# GPIO7 register map
Vendor: Texas Instruments
Peripheral module from a debugger description file (folder am574x).
Registers are 32-bit, read-write, reset 0x0 unless marked. A register's access mark holds for its fields unless they carry their own. Offsets are as the file gives them; lines under a group give offsets from that group; [hi:lo] are bit positions; {n}, {i} and the like mark numbered series; 'fields as' and 'values as' point back to an identical list; <NAME> marks a mode.

## GPIO7
0x00 GPIO_REVISION ro reset not defined — IP revision identifier (X.Y.R)
  [31:0] REVISION — IP revision
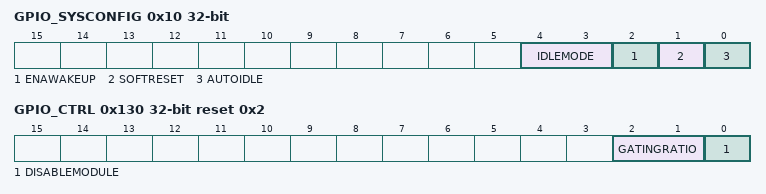
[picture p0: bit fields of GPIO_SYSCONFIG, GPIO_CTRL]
0x10 GPIO_SYSCONFIG access per field — System configuration register
  [4:3] IDLEMODE rw — 0x0: Force-idle: An IDLE request is acknowledged unconditionally.
    1=No-idle: An IDLE request is never acknowledged; 2=Smart-idle: The acknowledgment to an IDLE request is given based on the internal activity (see, System Power Management and Wakeup); 3=SmartIdleWakeup
  [2] ENAWAKEUP rw — Wake-up control.
    0=Disable (Wake-up generation is disabled.); 1=Enable (Wake-up capability is enabled upon expected transition on input GPIO pin)
  [1] SOFTRESET rw — Software reset. Set this bit to 1 to trigger a module reset. The bit is automatically reset by the hardware. During reads, it always returns 0.
    0=Normal mode; 1=Reset (The module is reset.)
  [0] AUTOIDLE rw — OCP clock gating control.
    0=FreeRun (Internal interface OCP clock is free-running.); 1=Automatic internal OCP clock gating, based on the OCP interface activity
0x20 GPIO_EOI access per field — Software end of interrupt.
  [0] LINE_NUMBER wo — Software End Of Interrupt (EOI) control.
    0=EOI_0 (EOI for interrupt line number 0. Read returns 0.); 1=EOI_1 (EOI for interrupt line number 1. Read returns 0.)
0x24 GPIO_IRQSTATUS_RAW_0 — Per-event raw interrupt status vector, showing all active events (enabled and not enabled), (corresponding to first line of interrupt)
  [31:0] INTLINE — Status raw for interrupt line. Writing '1' to a bit will set it to '1.' Writing '0' has no effect
0x28 GPIO_IRQSTATUS_RAW_1 — Per-event raw interrupt status vector, showing all active events (enabled and not enabled), (corresponding to second line of interrupt)
  [31:0] INTLINE — Status raw for interrupt line Writing '1' to a bit will set it to '1.' Writing '0' has no effect
0x2C GPIO_IRQSTATUS_0 — Per-event interrupt status vector, showing all active and enabled events (corresponding to first line of interrupt)
  [31:0] INTLINE — Status for interrupt line Writing 1 to a bit will clear it to 0. Writing 0 has no effect.
0x30 GPIO_IRQSTATUS_1 — Per-event enabled interrupt status vector, showing all active and enabled events (corresponding to second line of interrupt)
  fields as GPIO_IRQSTATUS_0
0x34 GPIO_IRQSTATUS_SET_0 — Per-event interrupt-enable set vector (corresponding to first line of interrupt)
  [31:0] INTLINE — Status set for interrupt line Writing 1 to a bit enables the corresponding interrupt event. Writing 0 has no effect.
0x38 GPIO_IRQSTATUS_SET_1 — Per-event enable set interrupt vector (corresponding to second line of interrupt)
  fields as GPIO_IRQSTATUS_SET_0
0x3C GPIO_IRQSTATUS_CLR_0 — Per-event interrupt-enable clear vector (corresponding to first line of interrupt)
  [31:0] INTLINE — Status clear for interrupt line Writing 1 to a bit disables the corresponding interrupt event. Writing 0 has no effect.
0x40 GPIO_IRQSTATUS_CLR_1 — Per-event enable clear interrupt vector (corresponding to second line of interrupt)
  fields as GPIO_IRQSTATUS_CLR_0
0x44 GPIO_IRQWAKEN_0 — Per-event wake-up enable set vector (corresponding to first line of interrupt)
  [31:0] INTLINE — Wakeup set for interrupt line Setting a bit to 1 will enable wakeup for the corresponding event. Setting a bit to 0 will disable wakeup for the corresponding event.
0x48 GPIO_IRQWAKEN_1 — Per-event wake-up enable set vector (corresponding to second line of interrupt)
  fields as GPIO_IRQWAKEN_0
0x114 GPIO_SYSSTATUS ro — System status register
  [0] RESETDONE
    0=InProgress (Internal reset is ongoing.); 1=Complete (Reset completed)
0x130 GPIO_CTRL access per field reset 0x2 — GPIO control register
  [2:1] GATINGRATIO rw — Clock gating ratio for event detection
    0=N_1; 1=N_2; 2=N_4; 3=N_8
  [0] DISABLEMODULE rw
    0=Enabled (Module is enabled, clocks are not gated.); 1=Disabled (Module is disabled, internal clocks are gated)
0x134 GPIO_OE reset 0xFFFFFFFF — Output enable register. 0 = Output enabled ; 1 = Output disabled
  [31:0] OUTPUTEN — Output enable
    0=Enabled (Output enabled); 1=Disabled (Output disabled)
0x138 GPIO_DATAIN ro — Data input register (with sampled input data)
  [31:0] DATAIN — Sampled input data
0x13C GPIO_DATAOUT — Data-output register (data to set on output pins)
  [31:0] DATAOUT — Data to set on output pins
0x140 GPIO_LEVELDETECT0 — Detect low-level register. 0 = Low-level detection disabled; 1 = Low-level detection enabled
  [31:0] LEVELDETECT0 — Low-level detection
    0=Disabled (Low-level detection disabled); 1=Enabled (Low-level detection enabled)
0x144 GPIO_LEVELDETECT1 — Detect high-level register
  [31:0] LEVELDETECT1
    0=Disabled (High-evel detection disabled); 1=Enabled (High-level detection enabled)
0x148 GPIO_RISINGDETECT — Detect rising edge register
  [31:0] RISINGDETECT
    0=Disabled (Rising edge detection disabled); 1=Enabled (Rising edge detection enabled)
0x14C GPIO_FALLINGDETECT — Detect falling edge register
  [31:0] FALLINGDETECT
    0=Disabled (Falling edge detection disabled); 1=Enabled (Falling edge detection enabled)
0x150 GPIO_DEBOUNCENABLE — Debouncing enable register
  [31:0] DEBOUNCEENABLE
    0=NoDebounce (No debouncing); 1=Debounce (Debouncing activated)
0x154 GPIO_DEBOUNCINGTIME access per field — Debouncing value register
  [7:0] DEBOUNCETIME rw — 8-bit values specifying the debouncing time. It is n-periods of the muxed clock, which can come from either a true 32k oscillator/pad of from the system clock. It depends on which boot mode is selected. For more information see, Initialization.
0x190 GPIO_CLEARDATAOUT — Clear data-output register
  [31:0] INTLINE
    0=No_effect; 1=Clear the corresponding bit in the data-output register
0x194 GPIO_SETDATAOUT — Set data-output register
  [31:0] INTLINE
    0=No_effect; 1=Set the corresponding bit in the data-output register
